# STM32H7R7xx register map
File version: 1.0
Registers are 32-bit, read-write, reset 0x0 unless marked. A register's access mark holds for its fields unless they carry their own. Offsets are from the block's base; [hi:lo] are bit positions; {n}, {i} and the like mark numbered series.

## DTS
Base 0x58006800
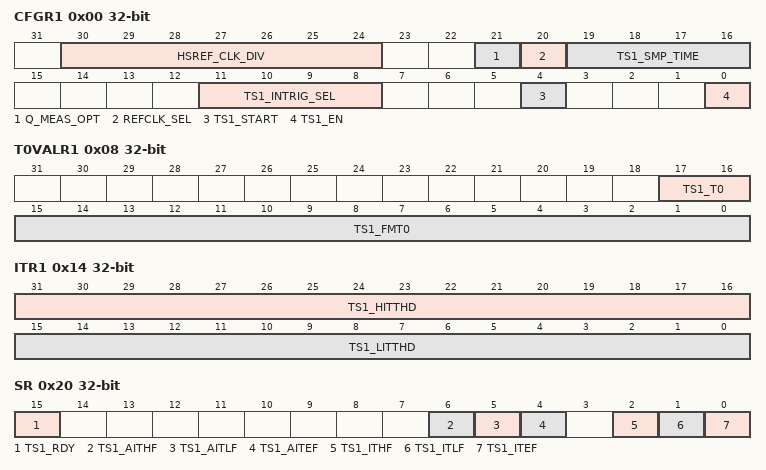
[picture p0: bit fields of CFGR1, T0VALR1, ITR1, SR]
0x00 CFGR1 — DTS configuration register
  [30:24] HSREF_CLK_DIV — High Speed Clock Divider Ratio [6:0]
  [21] Q_MEAS_OPT — Quick measure option bit
  [20] REFCLK_SEL — Reference Clock Selection
  [19:16] TS1_SMP_TIME — Sample time [3:0] for DTS
  [11:8] TS1_INTRIG_SEL — Input triggers selection bits [3:0] for DTS
  [4] TS1_START — Proceed to a frequency measurement on DTS
  [0] TS1_EN — DTS Enable
0x08 T0VALR1 — DTS T0 Value register
  [17:16] TS1_T0 — Engineering value of the DTSerature T0 for DTS
  [15:0] TS1_FMT0 — Engineering value of the measured frequency at T0 for DTS
0x10 RAMPVALR — DTS Ramp value register
  [15:0] TS1_RAMP_COEFF — Engineering value of the ramp coefficient for DTS
0x14 ITR1 — DTS Interrupt threshold register
  [31:16] TS1_HITTHD — High interrupt threshold[15:0] for DTS
  [15:0] TS1_LITTHD — Low interrupt threshold[15:0] for DTS
0x1C DR — DTS data register
  [15:0] TS1_MFREQ — Measured Frequency[15:0] for DTS
0x20 SR — DTS status register
  [15] TS1_RDY — DTS ready flag
  [6] TS1_AITHF — Asynchronous interrupt flag for high threshold for DTS
  [5] TS1_AITLF — Asynchronous interrupt flag for low threshold for DTS
  [4] TS1_AITEF — Asynchronous interrupt flag for end of measure for DTS
  [2] TS1_ITHF — Interrupt flag for high threshold for DTS
  [1] TS1_ITLF — Interrupt flag for low threshold for DTS
  [0] TS1_ITEF — Interrupt flag for end of measure for DTS
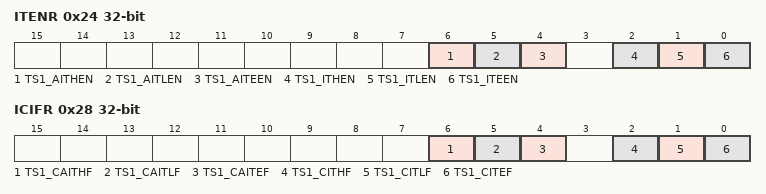
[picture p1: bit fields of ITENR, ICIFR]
0x24 ITENR — DTS Interrupt enable register
  [6] TS1_AITHEN — Enable asynchronous interrupt flag for high threshold for DTS
  [5] TS1_AITLEN — Enable Asynchronous interrupt flag for low threshold for DTS
  [4] TS1_AITEEN — Enable asynchronous interrupt flag for end of measure for DTS
  [2] TS1_ITHEN — Enable interrupt flag for high threshold for DTS
  [1] TS1_ITLEN — Enable interrupt flag for low threshold for DTS
  [0] TS1_ITEEN — Enable interrupt flag for end of measure for DTS
0x28 ICIFR — DTS Clear Interrupt flag register
  [6] TS1_CAITHF — Clear the asynchronous IT flag for high threshold on DTS
  [5] TS1_CAITLF — Clear the asynchronous IT flag for low threshold for DTS
  [4] TS1_CAITEF — Clear the asynchronous IT flag for End Of Measure for DTS
  [2] TS1_CITHF — Clear the IT flag for high threshold on DTS
  [1] TS1_CITLF — Clear the IT flag for low threshold for DTS
  [0] TS1_CITEF — Clear the IT flag for End Of Measure for DTS
0x2C OR — DTS option register 1

## GPIOA — General Purpose I/O
Base 0x58020000
Same registers: GPIOB 0x58020400, GPIOC 0x58020800, GPIOD 0x58020C00, GPIOE 0x58021000, GPIOF 0x58021400, GPIOG 0x58021800, GPIOH 0x58021C00, GPIOM 0x58023000, GPION 0x58023400, GPIOO 0x58023800, GPIOP 0x58023C00
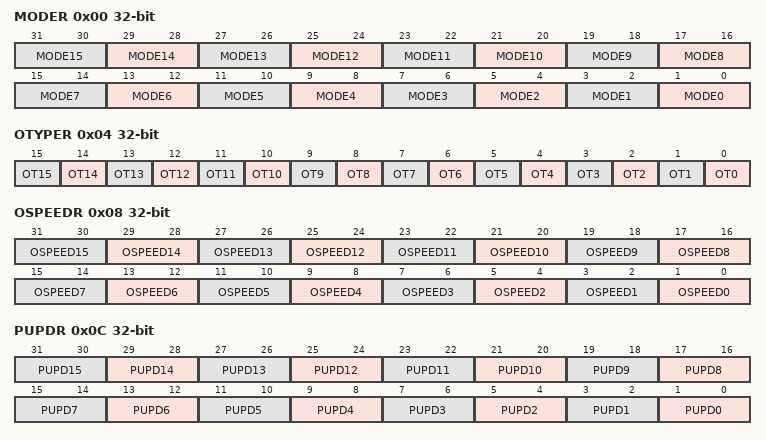
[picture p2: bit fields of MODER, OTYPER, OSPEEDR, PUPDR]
0x00 MODER — GPIO port mode register
  [2n+1:2n] MODE{n} (n=0..15)
0x04 OTYPER — GPIO port output type register
  [n] OT{n} (n=0..15)
0x08 OSPEEDR — GPIO port output speed register
  [2n+1:2n] OSPEED{n} (n=0..15)
0x0C PUPDR — GPIO port pull-up/pull-down register
  [2n+1:2n] PUPD{n} (n=0..15)
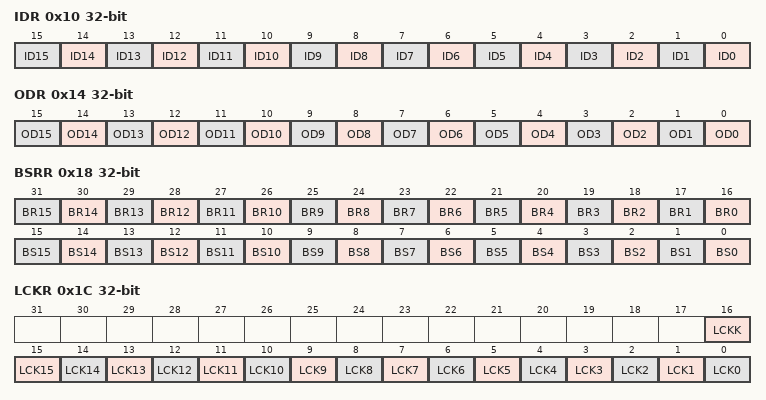
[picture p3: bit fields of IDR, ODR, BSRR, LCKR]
0x10 IDR — GPIO port input data register
  [n] ID{n} (n=0..15)
0x14 ODR — GPIO port output data register
  [n] OD{n} (n=0..15)
0x18 BSRR — GPIO port bit set/reset register
  [n+16] BR{n} (n=0..15), [n] BS{n} (n=0..15)
0x1C LCKR — GPIO port configuration lock register
  [16] LCKK, [n] LCK{n} (n=0..15)
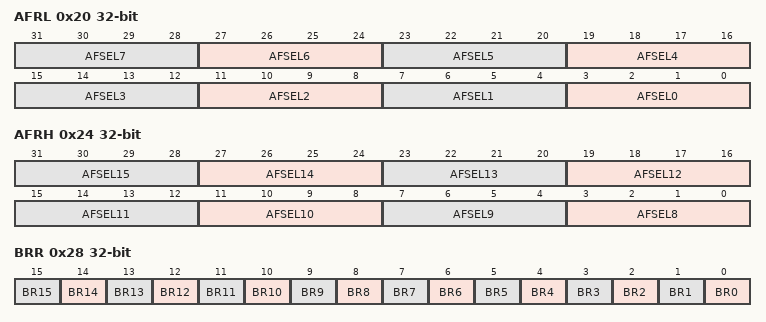
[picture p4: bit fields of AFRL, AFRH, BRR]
0x20 AFRL — GPIO alternate function registers
  [4n+3:4n] AFSEL{n} (n=0..7)
0x24 AFRH — GPIO alternate function registers
  [4n-29:4n-32] AFSEL{n} (n=8..15)
0x28 BRR — GPIO Bit Reset register
  [n] BR{n} (n=0..15)

## CRC — CRC calculation unit
Base 0x58024C00
0x00 DR — CRC Data register
  [31:0] DR — Data register bits
0x04 IDR — CRC Independent data register
  [31:0] IDR — General-purpose 32-bits data register bits
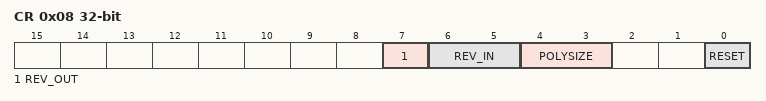
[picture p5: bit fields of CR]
0x08 CR — CRC Control register
  [7] REV_OUT — REV_OUT Reverse Output Data bits
    0=NONE (Output Data bit order not affected); 1=BIT (Output Data bit reversal done by bit)
  [6:5] REV_IN — REV_IN Reverse Input Data bits
    0=NONE (Input Data bit order not affected); 1=BYTE (Input Data bit reversal done by byte); 2=HALFWORD (Input Data bit reversal done by half-word); 3=WORD (Input Data bit reversal done by word)
  [4:3] POLYSIZE — Polynomial size bits
    0=POLYLENGTH_32B (32 bits Polynomial size); 1=POLYLENGTH_16B (16 bits Polynomial size); 2=POLYLENGTH_8B (8 bits Polynomial size); 3=POLYLENGTH_7B (7 bits Polynomial size)
  [0] RESET — RESET the CRC computation unit bit
0x10 INIT — Initial CRC value register
  [31:0] INIT — Initial CRC value bits
0x14 POL — CRC polynomial register
  [31:0] POL — Coefficients of the polynomial
